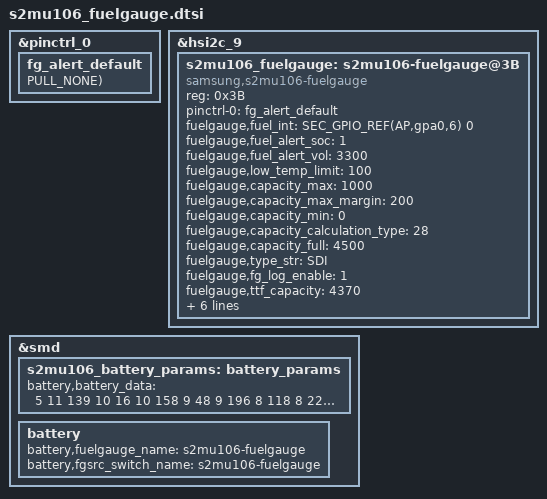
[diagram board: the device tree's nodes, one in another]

&pinctrl_0 {
	fg_alert_default: fg_alert_default {
		GPIO_CONFIG_PUD(AP,gpa0,6, FUNC_INPUT_WAKEUP, PULL_NONE);
	};
};

&hsi2c_9 {
	status = "okay";

	s2mu106_fuelgauge: s2mu106-fuelgauge@3B {
		compatible = "samsung,s2mu106-fuelgauge";
		reg = <0x3B>;
		pinctrl-names = "default";
		pinctrl-0 = <&fg_alert_default>;
		fuelgauge,fuel_int = <SEC_GPIO_REF(AP,gpa0,6) 0>;
		fuelgauge,fuel_alert_soc = <1>;
		fuelgauge,fuel_alert_vol = <3300>;
		fuelgauge,low_temp_limit = <100>;
		fuelgauge,capacity_max = <1000>;
		fuelgauge,capacity_max_margin = <200>;
		fuelgauge,capacity_min = <0>;
		fuelgauge,capacity_calculation_type = <28>;
		fuelgauge,capacity_full = <4370>;
		fuelgauge,type_str = "SDI";
		fuelgauge,fg_log_enable = <1>;

		fuelgauge,ttf_capacity = <4370>;
		fuelgauge,cv_data = <
			2488	829	1809
			2409	832	1796
			2327	837	1769
			2272	840	1743
			2182	846	1721
			2104	850	1690
			2038	854	1670
			1950	859	1640
			1904	861	1622
			1838	865	1594
			1797	867	1576
			1749	870	1560
			1703	873	1531
			1683	873	1525
			1667	875	1515
			1660	875	1512
			1653	876	1509
			1615	878	1502
			1580	880	1483
			1553	881	1463
			1544	882	1458
			1520	883	1451
			1477	886	1424
			1431	888	1409
			1396	891	1383
			1347	894	1361
			1299	896	1332
			1267	898	1315
			1231	902	1288
			1202	904	1263
			1148	906	1243
			1109	909	1213
			1067	911	1185
			1031	914	1156
			1013	915	1140
			975	917	1111
			961	919	1084
			921	921	1064
			892	923	1038
			887	923	1019
			863	925	1004
			833	927	976
			808	929	946
			787	930	918
			780	931	904
			764	932	895
			744	934	864
			730	935	846
			715	936	828
			693	937	800
			681	938	783
			666	940	752
			651	941	735
			640	942	712
			628	945	697
			622	946	679
			618	947	664
			600	950	646
			596	951	627
			589	953	614
			584	953	601
			576	956	572
			577	957	553
			562	958	535
			511	968	506
			505	969	487
			493	971	464
			492	972	435
			484	973	417
			480	975	398
			474	976	380
			470	977	364
			462	977	355
			456	978	336
			452	979	329
			446	981	303
			437	982	282
			429	984	255
			423	985	242
			422	986	229
			414	987	211
			411	988	199
			405	989	191
			397	990	171
			391	991	140
			387	992	126
			384	993	107
			372	995	84
			364	997	54
			356	998	26
			356	998	13
			0	1000	0
			>;
	};
};

&smd {
	s2mu106_battery_params: battery_params {
		battery,battery_data =
			<
			/***** battery data for 4.35 *****/
			/* battery,battery_table3 */
			5 11 139 10 16 10 158 9 48 9
			196 8 118 8 227 7 173 7 65 7
			236 6 182 6 139 6 104 6 76 6
			41 6 0 6 218 5 156 5 131 5
			156 4 133 1 106 8 0 8 150 7
			43 7 193 6 87 6 236 5 130 5
			24 5 174 4 67 4 217 3 111 3
			4 3 154 2 48 2 198 1 91 1
			241 0 135 0 28 0 214 15

			/* battery,battery_table4 */
			10 10 10 10 26 26 25 24 24 24
			23 23 24 24 25 26 27 28 29 31
			36 86

			/* battery,batcap */
			0x48 0x44 0xAC 0x0D /* [0x0E] [0x0F] [0x10] [0x11] */
			/* battery,accum */ 
			0x00 0x08 /* [0x44] [0x45] */

			/* battery,soc_arr_val */
			10519 10000 9480 8961 8442 7923 7404 6885 6366 5847
			5328 4809 4290 3771 3252 2733 2214 1695 1176 657
			138 (-204)

			/* battery,ocv_arr_val */
			43776 43177 42578 42019 41484 40959 40574 39857 39595 39069
			38654 38389 38177 38009 37872 37701 37498 37312 37010 36890
			35763 31899

			/* battery,tunning */
			0x00

			/***** battery data for 4.33 *****/
			/* battery,battery_table3 */
			5	11	139	10	16	10	158	9	48	9
			196	8	118	8	227	7	173	7	65	7
			236	6	182	6	139	6	104	6	76	6
			41	6	0	6	218	5	156	5	131	5
			156	4	133	1	159	8	50	8	197	7
			88	7	235	6	126	6	17	6	165	5
			56	5	203	4	94	4	241	3	132	3
			23	3	170	2	61	2	209	1	100	1
			247	0	138	0	29	0	213	15

			/* battery,battery_table4 */
			26	26	26	26	26	26	25	24	24	24
			23	23	24	24	25	26	27	28	29	31
			36	36

			/* battery,batcap */
			0x68 0x42 0x9A 0x10 /* [0x0E] [0x0F] [0x10] [0x11] */
			/* battery,accum */
			0x00 0x08 /* [0x44] [0x45] */

			/* battery,soc_arr_val */
			10775	10243	9711	9180	8648	8116	7585	7053	6521	5990
			5458	4926	4395	3863	3331	2800	2268	1736	1205	673
			141	(-209)

			/* battery,ocv_arr_val */
			43776	43177	42578	42019	41484	40959	40574	39857	39595	39069
			38654	38389	38177	38009	37872	37701	37498	37312	37010	36890
			35763	31899

			/* battery,tunning */
			0x00

			/***** battery data for 4.31 *****/
			/* battery,battery_table3 */
			5	11	139	10	16	10	158	9	48	9
			196	8	118	8	227	7	173	7	65	7
			236	6	182	6	139	6	104	6	76	6
			41	6	0	6	218	5	156	5	131	5
			156	4	133	1	197	8	86	8	231	7
			121	7	10	7	155	6	44	6	190	5
			79	5	224	4	113	4	2	4	148	3
			37	3	182	2	71	2	217	1	106	1
			251	0	140	0	30	0	212	15

			/* battery,battery_table4 */
			26	26	26	26	26	26	25	24	24	24
			23	23	24	24	25	26	27	28	29	31
			36	36

			/* battery,batcap */
			0x50 0x41 0x54 0x10 /* [0x0E] [0x0F] [0x10] [0x11] */
			/* battery,accum */
			0x00 0x08 /* [0x44] [0x45] */

			/* battery,soc_arr_val */
			10961	10420	9880	9339	8798	8257	7716	7175	6634	6093
			5553	5012	4471	3930	3389	2848	2307	1766	1225	685
			144	(-213)

			/* battery,ocv_arr_val */
			43776	43177	42578	42019	41484	40959	40574	39857	39595	39069
			38654	38389	38177	38009	37872	37701	37498	37312	37010	36890
			35763	31899

			/* battery,tunning */
			0x00

			/***** battery data for 4.29 *****/
			/* battery,battery_table3 */
			5	11	139	10	16	10	158	9	48	9
			196	8	118	8	227	7	173	7	65	7
			236	6	182	6	139	6	104	6	76	6
			41	6	0	6	218	5	156	5	131	5
			156	4	133	1	237	8	124	8	11	8
			154	7	42	7	185	6	72	6	215	5
			103	5	246	4	133	4	21	4	164	3
			51	3	194	2	82	2	225	1	112	1
			255	0	143	0	30	0	212	15

			/* battery,battery_table4 */
			26	26	26	26	26	26	25	24	24	24
			23	23	24	24	25	26	27	28	29	31
			36	36

			/* battery,batcap */
			0x38 0x40 0x0E 0x10 /* [0x0E] [0x0F] [0x10] [0x11] */
			/* battery,accum */
			0x00 0x08 /* [0x44] [0x45] */

			/* battery,soc_arr_val */
			11155	10604	10054	9503	8953	8403	7852	7302	6751	6201
			5650	5100	4550	3999	3449	2898	2348	1798	1247	697
			146	(-217)

			/* battery,ocv_arr_val */
			43776	43177	42578	42019	41484	40959	40574	39857	39595	39069
			38654	38389	38177	38009	37872	37701	37498	37312	37010	36890
			35763	31899

			/* battery,tunning */
			0x00

			/***** battery data for 4.24 *****/
			/* battery,battery_table3 */
			5	11	139	10	16	10	158	9	48	9
			196	8	118	8	227	7	173	7	65	7
			236	6	182	6	139	6	104	6	76	6
			41	6	0	6	218	5	156	5	131	5
			156	4	133	1	77	9	215	8	98	8
			236	7	119	7	1	7	140	6	22	6
			161	5	43	5	182	4	64	4	203	3
			86	3	224	2	107	2	245	1	128	1
			10	1	149	0	31	0	210	15

			/* battery,battery_table4 */
			26	26	26	26	26	26	25	24	24	24
			23	23	24	24	25	26	27	28	29	31
			36	36

			/* battery,batcap */
			0x08 0x3E 0x82 0x0F /* [0x0E] [0x0F] [0x10] [0x11] */
			/* battery,accum */
			0x00 0x08 /* [0x44] [0x45] */

			/* battery,soc_arr_val */
			11623	11050	10476	9903	9329	8756	8182	7608	7035	6461
			5888	5314	4741	4167	3594	3020	2447	1873	1300	726
			152	(-226)

			/* battery,ocv_arr_val */
			43776	43177	42578	42019	41484	40959	40574	39857	39595	39069
			38654	38389	38177	38009	37872	37701	37498	37312	37010	36890
			35763	31899

			/* battery,tunning */
			0x00
			>;
	};
};

&smd {
		battery {
			battery,fuelgauge_name = "s2mu106-fuelgauge";
			battery,fgsrc_switch_name = "s2mu106-fuelgauge"; /* Fuelgauge voltage source */
		};
};

/* /home/dpi/qb5_8814/workspace/P4_1716/android/kernel/kmodule/battery/fuelgauge/s2mu106_fuelgauge/s2mu106_fuelgauge.a71x.dtsi */

&s2mu106_fuelgauge {
		fuelgauge,capacity_full = <4500>;
		fuelgauge,low_voltage_limit_lowtemp = <3000>;
		fuelgauge,low_voltage_recover_lowtemp = <3550>;
		fuelgauge,i_socr_coeff = <133>;
		fuelgauge,t_socr_coeff = <13000>;
};

&s2mu106_battery_params {
		battery,battery_data =
			<
			/***** battery data for 4.35 *****/
			/* battery,battery_table3 */
			5 11 139 10 16 10 158 9 48 9
			196 8 118 8 227 7 173 7 65 7
			237 6 182 6 139 6 104 6 76 6
			41 6 0 6 218 5 156 5 131 5
			156 4 133 1 106 8 0 8 150 7
			44 7 194 6 89 6 239 5 133 5
			27 5 177 4 71 4 222 3 116 3
			10 3 160 2 54 2 204 1 99 1
			249 0 143 0 37 0 223 15

			/* battery,battery_table4 */
			10 10 10 10 26 26 25 24 24 24
			23 23 23 24 25 26 27 28 29 31
			36 154

			/* battery,batcap */
			0x48 0x44 0x1F 0x05 /* [0x0E] [0x0F] [0x10] [0x11] */
			/* battery,accum */ 
			0x00 0x08 /* [0x44] [0x45] */

			/* battery,soc_arr_val */
			10517 10000 9483 8966 8450 7933 7416 6899 6382 5866
			5349 4832 4315 3798 3282 2765 2248 1731 1214 698
			181 (-161)

			/* battery,ocv_arr_val */
			43776 43178 42579 42019 41484 40959 40575 39857 39596 39069
			38655 38390 38178 38010 37873 37702 37499 37313 37011 36890
			35763 31900

			/* battery,tunning */
			0x00

			/***** battery data for 4.33 *****/
			/* battery,battery_table3 */
			5	11	139	10	16	10	158	9	48	9
			196	8	118	8	227	7	173	7	65	7
			237	6	182	6	139	6	104	6	76	6
			41	6	0	6	218	5	156	5	131	5
			156	4	133	1	158	8	50	8	197	7
			89	7	236	6	128	6	20	6	167	5
			59	5	206	4	98	4	246	3	137	3
			29	3	176	2	68	2	216	1	107	1
			255	0	146	0	38	0	222	15

			/* battery,battery_table4 */
			10 10 10 10 26 26 25 24 24 24
			23 23 23 24 25 26 27 28 29 31
			36 154

			/* battery,batcap */
			0x68 0x42 0x9A 0x10 /* [0x0E] [0x0F] [0x10] [0x11] */
			/* battery,accum */
			0x00 0x08 /* [0x44] [0x45] */

			/* battery,soc_arr_val */
			10772 10242 9713 9184 8654 8125 7596 7066 6537 6008
			5478 4949 4420 3890 3361 2832 2303 1773 1244 715
			185 (-165)

			/* battery,ocv_arr_val */
			43776 43178 42579 42019 41484 40959 40575 39857 39596 39069
			38655 38390 38178 38010 37873 37702 37499 37313 37011 36890
			35763 31900

			/* battery,tunning */
			0x00

			/***** battery data for 4.31 *****/
			/* battery,battery_table3 */
			5	11	139	10	16	10	158	9	48	9
			196	8	118	8	227	7	173	7	65	7
			237	6	182	6	139	6	104	6	76	6
			41	6	0	6	218	5	156	5	131	5
			156	4	133	1	196	8	86	8	232	7
			121	7	11	7	157	6	46	6	192	5
			82	5	228	4	117	4	7	4	153	3
			43	3	188	2	78	2	224	1	113	1
			3	1	149	0	39	0	222	15

			/* battery,battery_table4 */
			10 10 10 10 26 26 25 24 24 24
			23 23 23 24 25 26 27 28 29 31
			36 154

			/* battery,batcap */
			0x50 0x41 0x54 0x10 /* [0x0E] [0x0F] [0x10] [0x11] */
			/* battery,accum */
			0x00 0x08 /* [0x44] [0x45] */

			/* battery,soc_arr_val */
			10957 10419 9881 9342 8804 8265 7727 7188 6650 6111
			5573 5035 4496 3958 3419 2881 2342 1804 1265 727
			188 (-168)

			/* battery,ocv_arr_val */
			43776 43178 42579 42019 41484 40959 40575 39857 39596 39069
			38655 38390 38178 38010 37873 37702 37499 37313 37011 36890
			35763 31900

			/* battery,tunning */
			0x00

			/***** battery data for 4.29 *****/
			/* battery,battery_table3 */
			5	11	139	10	16	10	158	9	48	9
			196	8	118	8	227	7	173	7	65	7
			237	6	182	6	139	6	104	6	76	6
			41	6	0	6	218	5	156	5	131	5
			156	4	133	1	235	8	123	8	11	8
			155	7	43	7	186	6	74	6	218	5
			106	5	250	4	137	4	25	4	169	3
			57	3	201	2	88	2	232	1	120	1
			8	1	151	0	39	0	221	15

			/* battery,battery_table4 */
			10 10 10 10 26 26 25 24 24 24
			23 23 23 24 25 26 27 28 29 31
			36 154

			/* battery,batcap */
			0x38 0x40 0x0E 0x10 /* [0x0E] [0x0F] [0x10] [0x11] */
			/* battery,accum */
			0x00 0x08 /* [0x44] [0x45] */

			/* battery,soc_arr_val */
			11150 10602 10054 9506 8958 8410 7862 7315 6767 6219
			5671 5123 4575 4027 3479 2931 2383 1835 1288 740
			192 (-170)

			/* battery,ocv_arr_val */
			43776 43178 42579 42019 41484 40959 40575 39857 39596 39069
			38655 38390 38178 38010 37873 37702 37499 37313 37011 36890
			35763 31900

			/* battery,tunning */
			0x00

			/***** battery data for 4.24 *****/
			/* battery,battery_table3 */
			5	11	139	10	16	10	158	9	48	9
			196	8	118	8	227	7	173	7	65	7
			237	6	182	6	139	6	104	6	76	6
			41	6	0	6	218	5	156	5	131	5
			156	4	133	1	75	9	214	8	97	8
			236	7	119	7	2	7	142	6	25	6
			164	5	47	5	186	4	69	4	208	3
			91	3	230	2	113	2	253	1	136	1
			19	1	158	0	41	0	220	15

			/* battery,battery_table4 */
			10 10 10 10 26 26 25 24 24 24
			23 23 23 24 25 26 27 28 29 31
			36 154

			/* battery,batcap */
			0x08 0x3E 0x82 0x0F /* [0x0E] [0x0F] [0x10] [0x11] */
			/* battery,accum */
			0x00 0x08 /* [0x44] [0x45] */

			/* battery,soc_arr_val */
			11616 11045 10474 9904 9333 8762 8191 7620 7050 6479
			5908 5337 4766 4195 3625 3054 2483 1912 1341 771
			200 (-178)

			/* battery,ocv_arr_val */
			43776 43178 42579 42019 41484 40959 40575 39857 39596 39069
			38655 38390 38178 38010 37873 37702 37499 37313 37011 36890
			35763 31900

			/* battery,tunning */
			0x00
			>;
};
